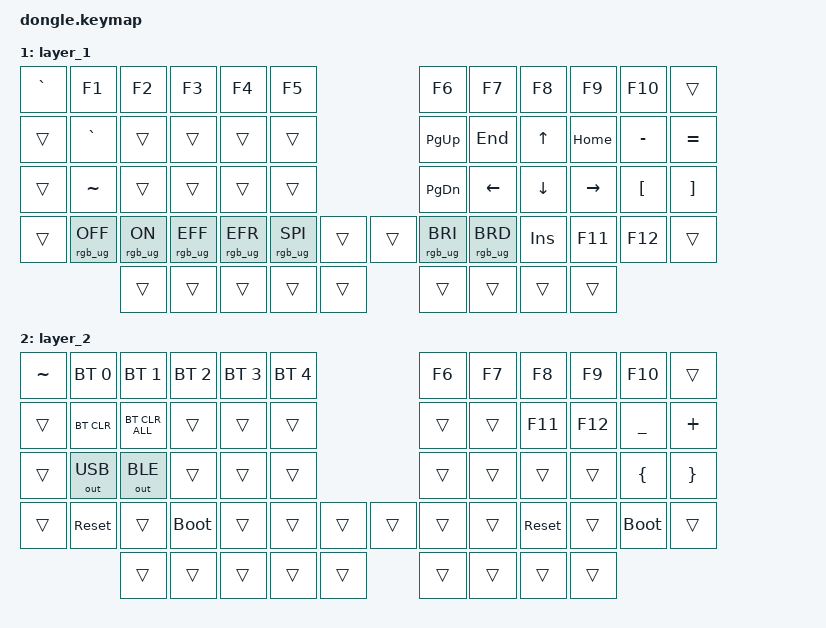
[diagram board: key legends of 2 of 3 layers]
/*
 * Copyright (c) 2024 The ZMK Contributors
 *
 * SPDX-License-Identifier: MIT
 */

#include <behaviors.dtsi>
#include <dt-bindings/zmk/keys.h>
#include <dt-bindings/zmk/bt.h>
#include <dt-bindings/zmk/rgb.h>
#include <dt-bindings/zmk/outputs.h>
#include <dt-bindings/zmk/ext_power.h>
#include <dt-bindings/zmk/matrix_transform.h>

/ {
    chosen {
        zmk,kscan = &mock_kscan;
        zmk,matrix-transform = &default_transform;
        zephyr,display = &oled;
    };

    mock_kscan: mock_kscan_0 {
        compatible = "zmk,kscan-mock";
        columns = <0>;
        rows = <0>;
        events = <0>;
    };

    // Matrix transform from alliecat_keeb
    default_transform: keymap_transform_0 {
        compatible = "zmk,matrix-transform";
        columns = <14>;
        rows = <5>;
        map = <
RC(0,0) RC(0,1) RC(0,2) RC(0,3) RC(0,4) RC(0,5)                 RC(0,8) RC(0,9) RC(0,10) RC(0,11) RC(0,12) RC(0,13)
RC(1,0) RC(1,1) RC(1,2) RC(1,3) RC(1,4) RC(1,5)                 RC(1,8) RC(1,9) RC(1,10) RC(1,11) RC(1,12) RC(1,13)
RC(2,0) RC(2,1) RC(2,2) RC(2,3) RC(2,4) RC(2,5)                 RC(2,8) RC(2,9) RC(2,10) RC(2,11) RC(2,12) RC(2,13)
RC(3,0) RC(3,1) RC(3,2) RC(3,3) RC(3,4) RC(3,5) RC(3,6) RC(3,7) RC(3,8) RC(3,9) RC(3,10) RC(3,11) RC(3,12) RC(3,13)
                RC(4,2) RC(4,3) RC(4,4) RC(4,5) RC(4,6) RC(4,7) RC(4,8) RC(4,9) RC(4,10) RC(4,11)
        >;
    };

    keymap {
        compatible = "zmk,keymap";

        default_layer {
            bindings = <
                &none &none &none &none &none &none
            >;
        };

        layer_1 {
            bindings = <
&kp GRAVE   &kp F1           &kp F2          &kp F3           &kp F4           &kp F5                           &kp F6           &kp F7           &kp F8      &kp F9     &kp F10           &trans
&trans      &kp GRAVE        &trans          &trans           &trans           &trans                           &kp PG_UP        &kp END          &kp UP      &kp HOME   &kp MINUS         &kp EQUAL
&trans      &kp TILDE        &trans          &trans           &trans           &trans                           &kp PG_DN        &kp LEFT         &kp DOWN    &kp RIGHT  &kp LEFT_BRACKET  &kp RIGHT_BRACKET
&trans      &rgb_ug RGB_OFF  &rgb_ug RGB_ON  &rgb_ug RGB_EFF  &rgb_ug RGB_EFR  &rgb_ug RGB_SPI  &trans  &trans  &rgb_ug RGB_BRI  &rgb_ug RGB_BRD  &kp INSERT  &kp F11    &kp F12           &trans
                             &trans          &trans           &trans           &trans           &trans          &trans           &trans           &trans      &trans
            >;
        };

        layer_2 {
            bindings = <
&kp TILDE  &bt BT_SEL 0  &bt BT_SEL 1    &bt BT_SEL 2  &bt BT_SEL 3  &bt BT_SEL 4                    &kp F6  &kp F7  &kp F8      &kp F9     &kp F10      &trans
&trans     &bt BT_CLR    &bt BT_CLR_ALL  &trans        &trans        &trans                          &trans  &trans  &kp F11     &kp F12    &kp UNDER    &kp PLUS
&trans     &out OUT_USB  &out OUT_BLE    &trans        &trans        &trans                          &trans  &trans  &trans      &trans     &kp LBRC     &kp RBRC
&trans     &sys_reset    &trans          &bootloader   &trans        &trans       &trans     &trans  &trans  &trans  &sys_reset  &trans     &bootloader  &trans
                         &trans          &trans        &trans        &trans       &trans             &trans  &trans  &trans      &trans
            >;
        };
    };
};

// Add I2C configuration for OLED display
&pro_micro_i2c {
    status = "okay";

    oled: ssd1306@3c {
        compatible = "solomon,ssd1306fb";
        reg = <0x3c>;
        width = <128>;
        height = <64>;
        segment-offset = <0>;
        page-offset = <0>;
        display-offset = <0>;
        multiplex-ratio = <63>;
        segment-remap;
        com-invdir;
        inversion-on;
        prechargep = <0x22>;
    };
};

&msc {
    acceleration-exponent = <1>;
    time-to-max-speed-ms = <100>;
    delay-ms = <0>;
};

// Matrix transform from alliecat_keeb
#include "alliecat_keeb.keymap"
